# PIC32MZ0512EFF144 device description
Architecture: 32xxxx; Family: PIC32MZEF; Series: PIC32MZ
Registers are 32-bit, read-write, no defined reset value unless marked. A register's access mark holds for its fields unless they carry their own. Offsets are from the block's base; [hi:lo] are bit positions; lines under a group give offsets from that group; {n}, {i} and the like mark numbered series; 'fields as' and 'values as' point back to an identical list.

## SB
Instances: SB 0x1f8f0510 in periph_ssx
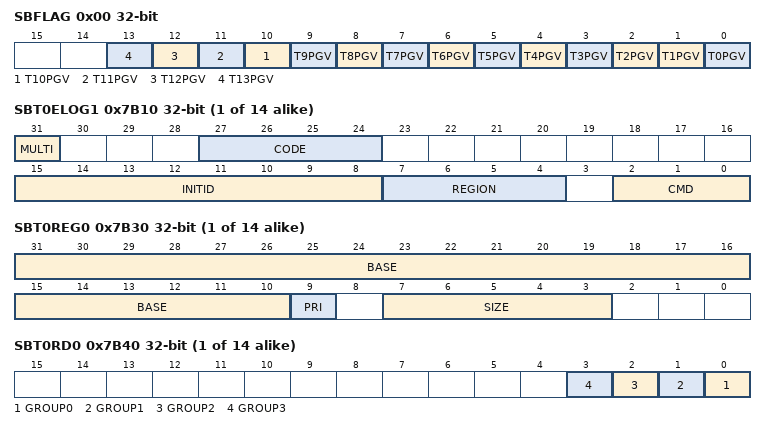
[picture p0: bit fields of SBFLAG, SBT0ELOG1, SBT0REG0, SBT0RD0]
0x00 SBFLAG ro — System Bus Status Flag Register
  [all] fields
    1=Target is reporting a Permission Group (PG) violation; 0=Target is not reporting a PG violation
  [n] T{n}PGV (n=2..13) — Target {n} Permission Group Violation Status bits
  [1] T1PGV — Target 1Permission Group Violation Status bits
  [0] T0PGV — Target 0 Permission Group Violation Status bits
{0x7B10+0x400*i} SBT{i}ELOG1 ro (i=0..13) — System Bus Target 'x' Error Log Register 1
  [31] MULTI — Multiple Permission Violations Status bit
    1=Multiple errors have been detected; 0=No multiple errors have been detected
  [27:24] CODE — Error Code bits
    3=Permission violation; 0=No error
  [15:8] INITID — Initiator ID of Requester bits
    14=Crypto Engine; 13=Flash Controller; 12=SQI1; 11=CAN2; 10=CAN1; 9=Ethernet Write; 8=Ethernet Read; 7=USB; 6=DMA Write (DMAPRI (CFGCON) = 1); 5=DMA Write (DMAPRI (CFGCON) = 0); 4=DMA Read (DMAPRI (CFGCON) = 1); 3=DMA Read (DMAPRI (CFGCON) = 0); 2=CPU (CPUPRI (CFGCON) = 1); 1=CPU (CPUPRI (CFGCON) = 0)
  [7:4] REGION — Requested Region Number bits
    1111 - 0000=Targets region that reported a permission group violation
  [2:0] CMD — Transaction Command of the Requester bits
    5=Write (a non-posted write); 3=Read (a locked read caused by a Read-Modify-Write transaction); 2=Read; 1=Write; 0=Idle
{0x7B14+0x400*i} SBT{i}ELOG2 ro (i=0..13) — System Bus Target 'x' Error Log Register 2
  [1:0] GROUP — Requested Permissions Group bits
    {v}=Group {v} (v=0..3)
{0x7B18+0x400*i} SBT{i}ECON (i=0..13) — System Bus Target 'x' Error Control Register
  [24] ERRP — Error Control bit
    1=Report protection group violation errors; 0=Do not report protection group violation errors
{0x7B20+0x400*i} SBT{i}ECLRS ro (i=0..13) — System Bus Target 'x' Single Error Clear Register
  [0] CLEAR
{0x7B28+0x400*i} SBT{i}ECLRM ro (i=0..13) — System Bus Target 'x' Multiple Error Clear Register
  [0] CLEAR
{0x7B30+0x400*i} SBT{i}REG0 (i=0..13)
  [31:10] BASE
  [9] PRI — Region Priority Level bit
    1=Level 2; 0=Level 1
  [7:3] SIZE — Region Size bits
    0=Region is not present; 1=Region is 1024 bytes; 2=Region is 2048 bytes; 3=Region is 4096 bytes
{0x7B40+0x400*i} SBT{i}RD0 (i=0..13)
  [n] GROUP{n} (n=0..3) — Group{n} Read Permissions bits
    1=Privilege Group {n} has read permission; 0=Privilege Group {n} does not have read permission
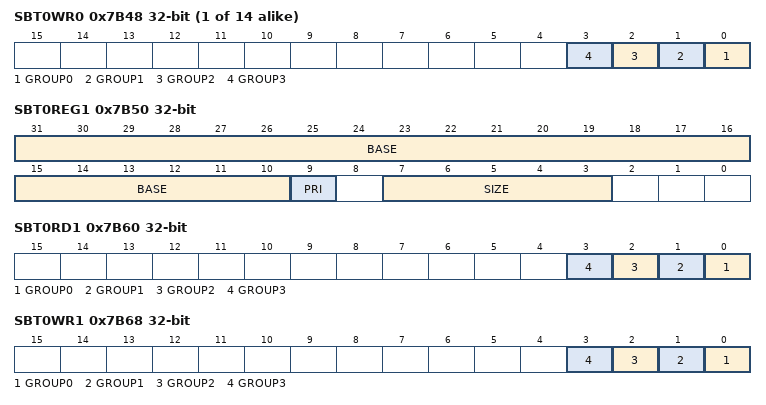
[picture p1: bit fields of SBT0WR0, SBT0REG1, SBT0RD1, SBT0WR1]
{0x7B48+0x400*i} SBT{i}WR0 (i=0..13)
  [n] GROUP{n} (n=0..3) — Group {n} Write Permissions bits
    1=Privilege Group {n} has write permission; 0=Privilege Group {n} does not have write permission
0x7B50 SBT0REG1
  fields as SBT0REG0
0x7B60 SBT0RD1
  fields as SBT0RD0
0x7B68 SBT0WR1
  fields as SBT0WR0
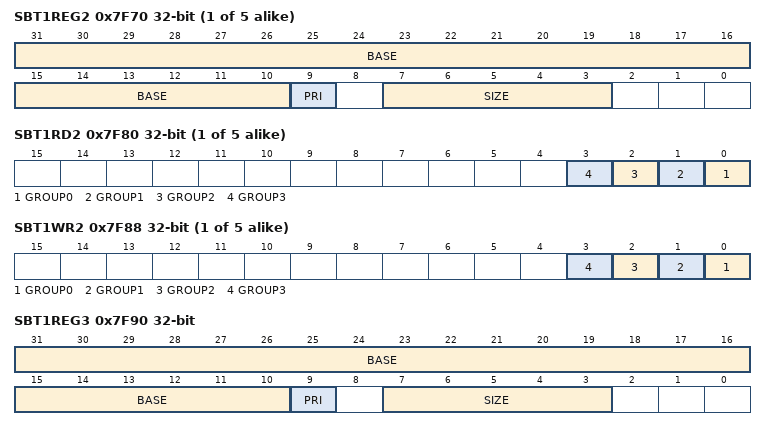
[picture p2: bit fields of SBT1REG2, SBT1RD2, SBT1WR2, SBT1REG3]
{0x7B70+0x400*i} SBT{i}REG2 (i=1..5)
  fields as SBT0REG0
{0x7B80+0x400*i} SBT{i}RD2 (i=1..5)
  fields as SBT0RD0
{0x7B88+0x400*i} SBT{i}WR2 (i=1..5)
  fields as SBT0WR0
0x7F90 SBT1REG3
  fields as SBT0REG0
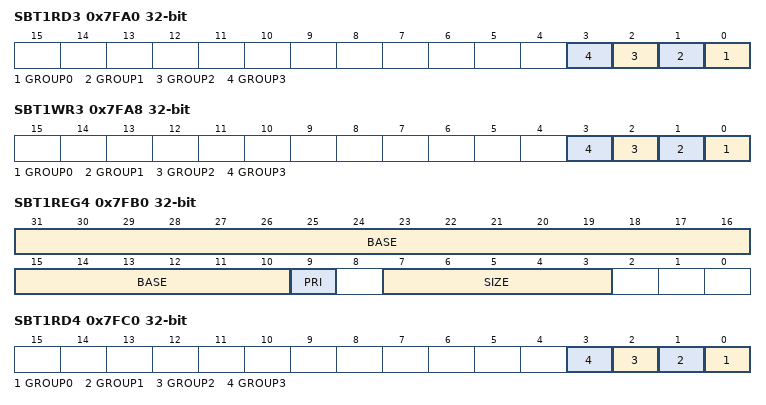
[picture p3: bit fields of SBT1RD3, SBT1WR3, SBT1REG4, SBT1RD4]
0x7FA0 SBT1RD3
  fields as SBT0RD0
0x7FA8 SBT1WR3
  fields as SBT0WR0
0x7FB0 SBT1REG4
  fields as SBT0REG0
0x7FC0 SBT1RD4
  fields as SBT0RD0
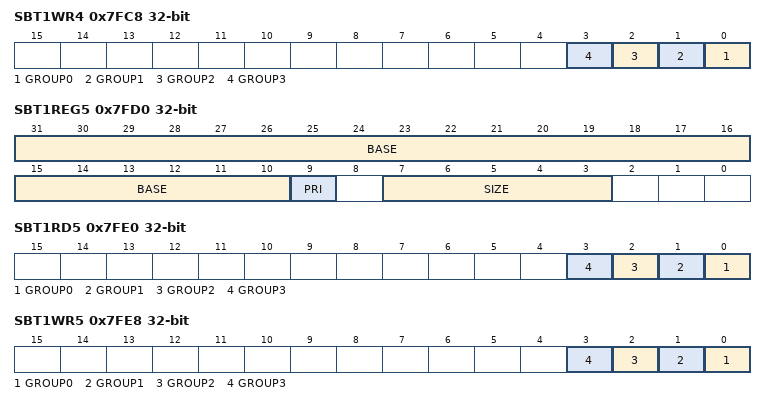
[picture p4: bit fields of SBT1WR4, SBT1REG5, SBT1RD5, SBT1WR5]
0x7FC8 SBT1WR4
  fields as SBT0WR0
0x7FD0 SBT1REG5
  fields as SBT0REG0
0x7FE0 SBT1RD5
  fields as SBT0RD0
0x7FE8 SBT1WR5
  fields as SBT0WR0
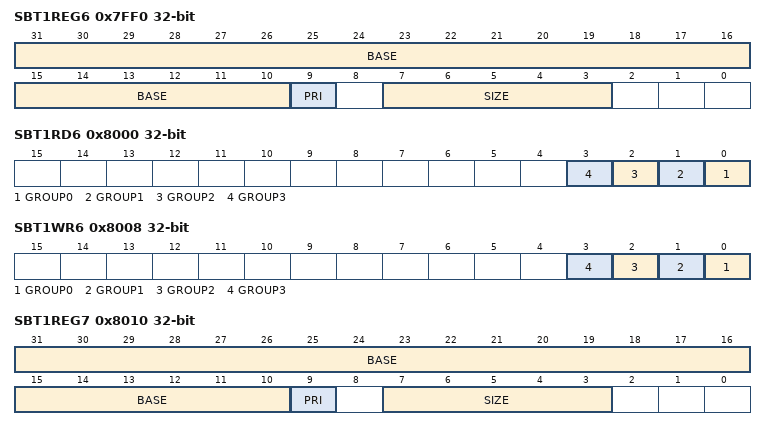
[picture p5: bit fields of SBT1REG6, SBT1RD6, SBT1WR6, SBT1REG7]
0x7FF0 SBT1REG6
  fields as SBT0REG0
0x8000 SBT1RD6
  fields as SBT0RD0
0x8008 SBT1WR6
  fields as SBT0WR0
0x8010 SBT1REG7
  fields as SBT0REG0
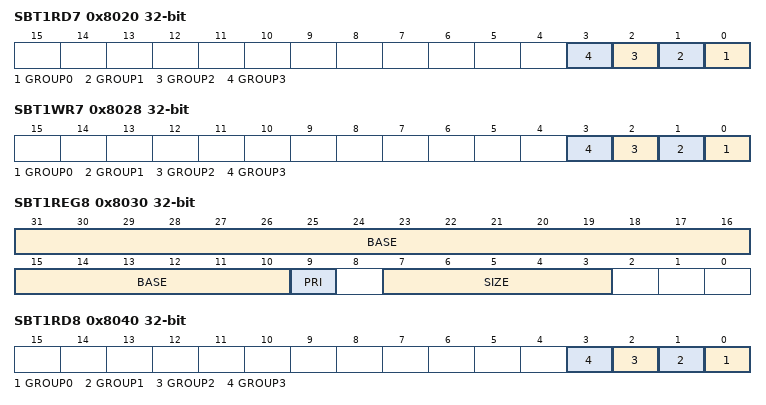
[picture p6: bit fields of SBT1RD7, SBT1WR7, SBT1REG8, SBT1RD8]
0x8020 SBT1RD7
  fields as SBT0RD0
0x8028 SBT1WR7
  fields as SBT0WR0
0x8030 SBT1REG8
  fields as SBT0REG0
0x8040 SBT1RD8
  fields as SBT0RD0
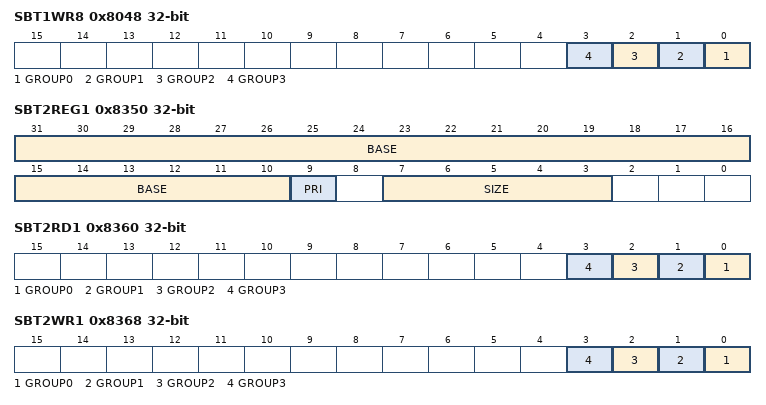
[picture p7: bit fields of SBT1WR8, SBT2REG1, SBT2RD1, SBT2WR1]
0x8048 SBT1WR8
  fields as SBT0WR0
0x8350 SBT2REG1
  fields as SBT0REG0
0x8360 SBT2RD1
  fields as SBT0RD0
0x8368 SBT2WR1
  fields as SBT0WR0
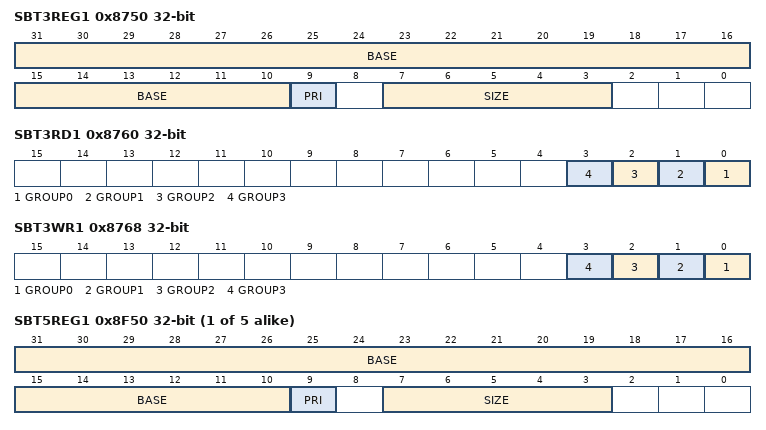
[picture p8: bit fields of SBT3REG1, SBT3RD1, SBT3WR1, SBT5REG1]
0x8750 SBT3REG1
  fields as SBT0REG0
0x8760 SBT3RD1
  fields as SBT0RD0
0x8768 SBT3WR1
  fields as SBT0WR0
{0x7B50+0x400*i} SBT{i}REG1 (i=5..9)
  fields as SBT0REG0
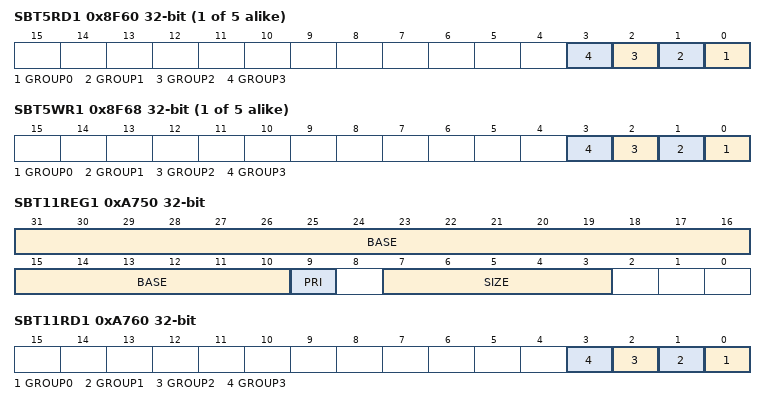
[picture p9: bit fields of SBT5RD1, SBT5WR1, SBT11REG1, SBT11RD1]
{0x7B60+0x400*i} SBT{i}RD1 (i=5..9)
  fields as SBT0RD0
{0x7B68+0x400*i} SBT{i}WR1 (i=5..9)
  fields as SBT0WR0
0xA750 SBT11REG1
  fields as SBT0REG0
0xA760 SBT11RD1
  fields as SBT0RD0
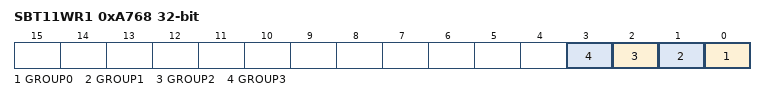
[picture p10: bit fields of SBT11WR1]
0xA768 SBT11WR1
  fields as SBT0WR0
